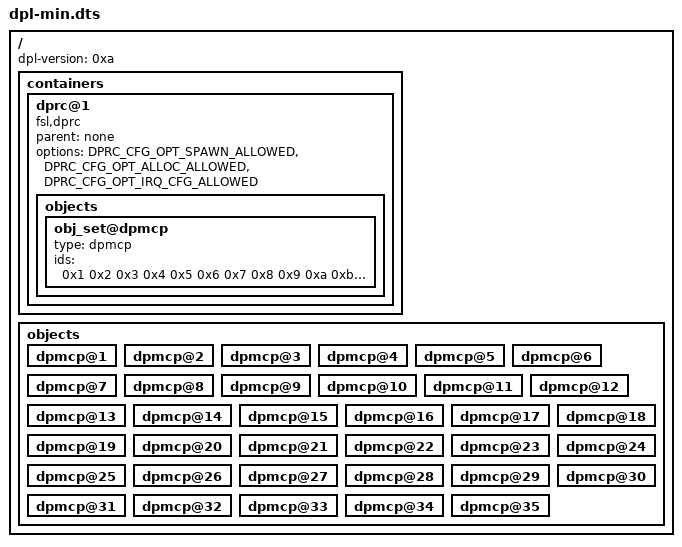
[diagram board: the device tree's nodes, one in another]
/*
 * Copyright 2014-2016 Freescale Semiconductor, Inc.
 * Copyright 2017 NXP
 *
 * Redistribution and use in source and binary forms, with or without
 * modification, are permitted provided that the following conditions are met:
 *   * Redistributions of source code must retain the above copyright
 *     notice, this list of conditions and the following disclaimer.
 *   * Redistributions in binary form must reproduce the above copyright
 *     notice, this list of conditions and the following disclaimer in the
 *     documentation and/or other materials provided with the distribution.
 *   * Neither the name of the above-listed copyright holders nor the
 *     names of any contributors may be used to endorse or promote products
 *     derived from this software without specific prior written permission.
 *
 * THIS SOFTWARE IS PROVIDED BY THE COPYRIGHT HOLDERS AND CONTRIBUTORS "AS IS"
 * AND ANY EXPRESS OR IMPLIED WARRANTIES, INCLUDING, BUT NOT LIMITED TO, THE
 * IMPLIED WARRANTIES OF MERCHANTABILITY AND FITNESS FOR A PARTICULAR PURPOSE
 * ARE DISCLAIMED. IN NO EVENT SHALL THE COPYRIGHT HOLDERS OR CONTRIBUTORS BE
 * LIABLE FOR ANY DIRECT, INDIRECT, INCIDENTAL, SPECIAL, EXEMPLARY, OR
 * CONSEQUENTIAL DAMAGES (INCLUDING, BUT NOT LIMITED TO, PROCUREMENT OF
 * SUBSTITUTE GOODS OR SERVICES; LOSS OF USE, DATA, OR PROFITS; OR BUSINESS
 * INTERRUPTION) HOWEVER CAUSED AND ON ANY THEORY OF LIABILITY, WHETHER IN
 * CONTRACT, STRICT LIABILITY, OR TORT (INCLUDING NEGLIGENCE OR OTHERWISE)
 * ARISING IN ANY WAY OUT OF THE USE OF THIS SOFTWARE, EVEN IF ADVISED OF THE
 * POSSIBILITY OF SUCH DAMAGE.
 */

/*
 * "Bootstrap DPL" for ls2088a RDB boards featuring SerDes 0x2A_0x41.
 * This DPL defines one network interface mapped on the ETH0 copper port.
 * This together with the available DPMCP objects should be enough to boot Linux
 * and to allow the dynamic addition of other objects to the Linux container,
 * using the 'restool' utility.
 */
/dts-v1/;
/ {
	dpl-version = <0xa>;
	/*****************************************************************
	 * Containers
	 *****************************************************************/
	containers {
		dprc@1 {
			compatible = "fsl,dprc";
			parent = "none";
			options = "DPRC_CFG_OPT_SPAWN_ALLOWED" , "DPRC_CFG_OPT_ALLOC_ALLOWED", "DPRC_CFG_OPT_IRQ_CFG_ALLOWED";
			objects {
				/* ------------ DPMCPs --------------*/
				/* ------------ DPMCPs --------------*/
				obj_set@dpmcp {
					type = "dpmcp";
					ids = <0x1 0x2 0x3 0x4 0x5 0x6 0x7 0x8 0x9 0xa 0xb 0xc 0xd 0xe 0xf 0x10 0x11 0x12 0x13 0x14 0x15 0x16 0x17 0x18 0x19 0x1a 0x1b 0x1c 0x1d 0x1e 0x1f 0x20 0x21 0x22 0x23>;
				};
			};
		};
	};

	/*****************************************************************
	 * Objects
	 *****************************************************************/
	objects {
		/* ------------ DPMCP --------------*/
		dpmcp@1 {
		};

		dpmcp@2 {
		};

		dpmcp@3 {
		};

		dpmcp@4 {
		};

		dpmcp@5 {
		};

		dpmcp@6 {
		};

		dpmcp@7 {
		};

		dpmcp@8 {
		};

		dpmcp@9 {
		};

		dpmcp@10 {
		};

		dpmcp@11 {
		};

		dpmcp@12 {
		};

		dpmcp@13 {
		};

		dpmcp@14 {
		};

		dpmcp@15 {
		};

		dpmcp@16 {
		};

		dpmcp@17 {
		};

		dpmcp@18 {
		};

		dpmcp@19 {
		};

		dpmcp@20 {
		};

		dpmcp@21 {
		};

		dpmcp@22 {
		};

		dpmcp@23 {
		};

		dpmcp@24 {
		};

		dpmcp@25 {
		};

		dpmcp@26 {
		};

		dpmcp@27 {
		};

		dpmcp@28 {
		};

		dpmcp@29 {
		};

		dpmcp@30 {
		};

		dpmcp@31 {
		};

		dpmcp@32 {
		};

		dpmcp@33 {
		};

		dpmcp@34 {
		};

		dpmcp@35 {
		};
	};
};
